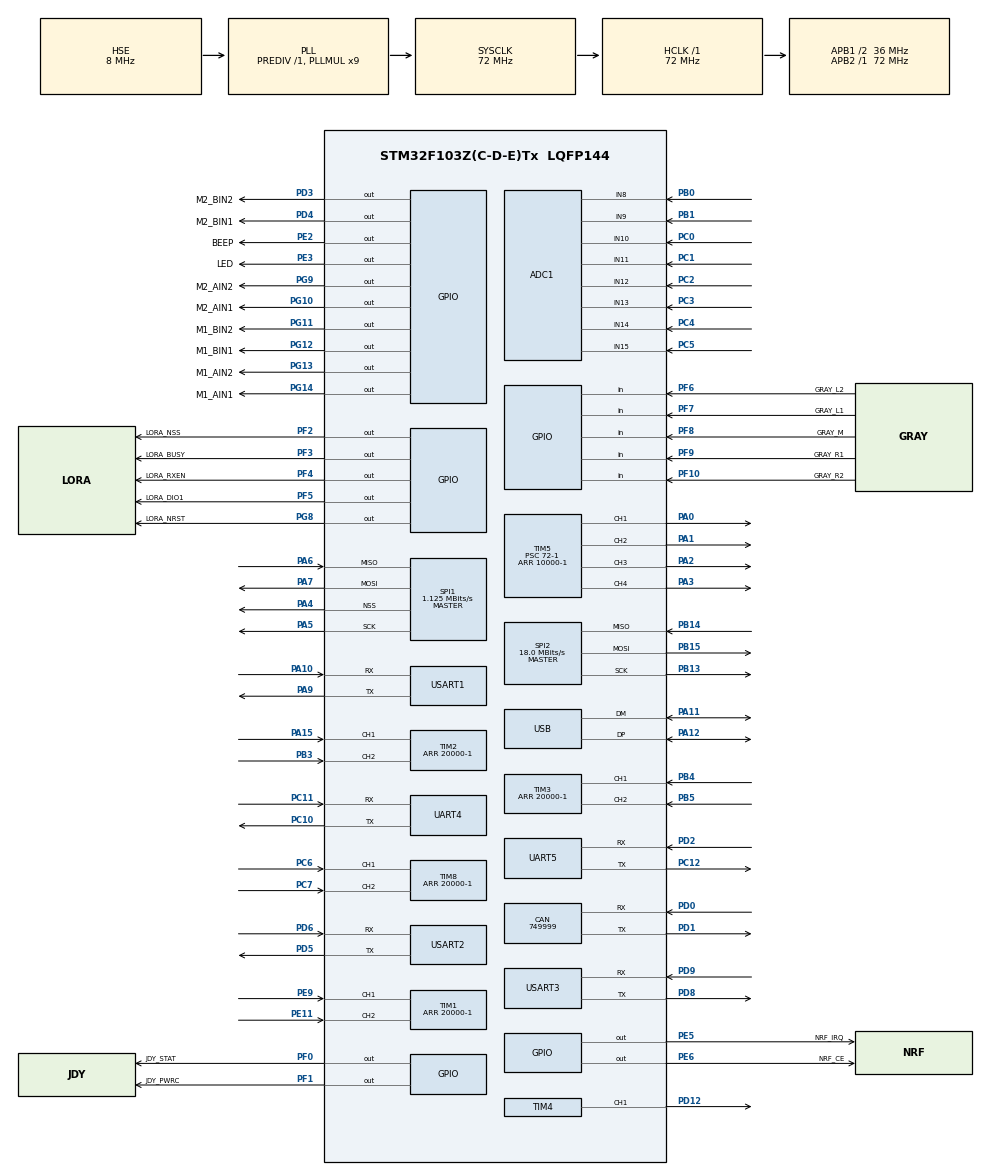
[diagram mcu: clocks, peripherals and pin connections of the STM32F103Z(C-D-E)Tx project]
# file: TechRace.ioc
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ADC1.Channel-1\#ChannelRegularConversion=ADC_CHANNEL_8
ADC1.Channel-2\#ChannelRegularConversion=ADC_CHANNEL_9
ADC1.Channel-4\#ChannelRegularConversion=ADC_CHANNEL_10
ADC1.Channel-5\#ChannelRegularConversion=ADC_CHANNEL_11
ADC1.Channel-6\#ChannelRegularConversion=ADC_CHANNEL_12
ADC1.Channel-7\#ChannelRegularConversion=ADC_CHANNEL_13
ADC1.Channel-8\#ChannelRegularConversion=ADC_CHANNEL_14
ADC1.Channel-9\#ChannelRegularConversion=ADC_CHANNEL_15
ADC1.ContinuousConvMode=ENABLE
ADC1.DataAlign=ADC_DATAALIGN_RIGHT
ADC1.NbrOfConversion=8
ADC1.NbrOfConversionFlag=1
ADC1.Rank-1\#ChannelRegularConversion=1
ADC1.Rank-2\#ChannelRegularConversion=2
ADC1.Rank-4\#ChannelRegularConversion=3
ADC1.Rank-5\#ChannelRegularConversion=4
ADC1.Rank-6\#ChannelRegularConversion=5
ADC1.Rank-7\#ChannelRegularConversion=6
ADC1.Rank-8\#ChannelRegularConversion=7
ADC1.Rank-9\#ChannelRegularConversion=8
ADC1.SamplingTime-1\#ChannelRegularConversion=ADC_SAMPLETIME_55CYCLES_5
ADC1.SamplingTime-2\#ChannelRegularConversion=ADC_SAMPLETIME_55CYCLES_5
ADC1.SamplingTime-4\#ChannelRegularConversion=ADC_SAMPLETIME_55CYCLES_5
ADC1.SamplingTime-5\#ChannelRegularConversion=ADC_SAMPLETIME_55CYCLES_5
ADC1.SamplingTime-6\#ChannelRegularConversion=ADC_SAMPLETIME_55CYCLES_5
ADC1.SamplingTime-7\#ChannelRegularConversion=ADC_SAMPLETIME_55CYCLES_5
ADC1.SamplingTime-8\#ChannelRegularConversion=ADC_SAMPLETIME_55CYCLES_5
ADC1.SamplingTime-9\#ChannelRegularConversion=ADC_SAMPLETIME_55CYCLES_5
ADC1.master=1
CAN.CalculateBaudRate=749999
CAN.CalculateTimeBit=1333
CAN.CalculateTimeQuantum=444.44444444444446
Dma.ADC1.0.Direction=DMA_PERIPH_TO_MEMORY
Dma.ADC1.0.Instance=DMA1_Channel1
Dma.ADC1.0.MemDataAlignment=DMA_MDATAALIGN_HALFWORD
Dma.ADC1.0.MemInc=DMA_MINC_ENABLE
Dma.ADC1.0.Mode=DMA_CIRCULAR
Dma.ADC1.0.PeriphDataAlignment=DMA_PDATAALIGN_HALFWORD
Dma.ADC1.0.PeriphInc=DMA_PINC_DISABLE
Dma.ADC1.0.Priority=DMA_PRIORITY_LOW
Dma.Request0=ADC1
Mcu.Family=STM32F1
Mcu.Name=STM32F103Z(C-D-E)Tx
Mcu.Package=LQFP144
NVIC.ADC1_2_IRQn=true\:2\:0\:true\:false\:true\:true\:true\:true
NVIC.DMA1_Channel1_IRQn=true\:0\:0\:false\:false\:true\:false\:true\:true
NVIC.PriorityGroup=NVIC_PRIORITYGROUP_4
NVIC.TIM6_IRQn=true\:0\:0\:false\:false\:true\:true\:true\:true
OSC_IN.Mode=HSE-External-Oscillator
OSC_IN.Signal=RCC_OSC_IN
OSC_OUT.Mode=HSE-External-Oscillator
OSC_OUT.Signal=RCC_OSC_OUT
PA0-WKUP.Signal=S_TIM5_CH1
PA1.Signal=S_TIM5_CH2
PA10.Mode=Asynchronous
PA10.Signal=USART1_RX
PA11.Mode=Device
PA11.Signal=USB_DM
PA12.Mode=Device
PA12.Signal=USB_DP
PA13.Mode=Serial_Wire
PA13.Signal=SYS_JTMS-SWDIO
PA14.Mode=Serial_Wire
PA14.Signal=SYS_JTCK-SWCLK
PA15.Signal=S_TIM2_CH1_ETR
PA2.Signal=S_TIM5_CH3
PA3.Signal=S_TIM5_CH4
PA4.Mode=NSS_Signal_Hard_Output
PA4.Signal=SPI1_NSS
PA5.Mode=Full_Duplex_Master
PA5.Signal=SPI1_SCK
PA6.Mode=Full_Duplex_Master
PA6.Signal=SPI1_MISO
PA7.Mode=Full_Duplex_Master
PA7.Signal=SPI1_MOSI
PA9.Mode=Asynchronous
PA9.Signal=USART1_TX
PB0.Signal=ADCx_IN8
PB1.Signal=ADCx_IN9
PB13.Mode=Full_Duplex_Master
PB13.Signal=SPI2_SCK
PB14.Mode=Full_Duplex_Master
PB14.Signal=SPI2_MISO
PB15.Mode=Full_Duplex_Master
PB15.Signal=SPI2_MOSI
PB3.Signal=S_TIM2_CH2
PB4.Signal=S_TIM3_CH1
PB5.Signal=S_TIM3_CH2
PC0.Signal=ADCx_IN10
PC1.Signal=ADCx_IN11
PC10.Mode=Asynchronous
PC10.Signal=UART4_TX
PC11.Mode=Asynchronous
PC11.Signal=UART4_RX
PC12.Mode=Asynchronous
PC12.Signal=UART5_TX
PC2.Signal=ADCx_IN12
PC3.Signal=ADCx_IN13
PC4.Signal=ADCx_IN14
PC5.Signal=ADCx_IN15
PC6.Signal=S_TIM8_CH1
PC7.Signal=S_TIM8_CH2
PD0.Mode=CAN_Activate
PD0.Signal=CAN_RX
PD1.Mode=CAN_Activate
PD1.Signal=CAN_TX
PD12.Signal=S_TIM4_CH1
PD2.Mode=Asynchronous
PD2.Signal=UART5_RX
PD3.GPIO_Label=M2_BIN2
PD3.Signal=GPIO_Output
PD4.GPIO_Label=M2_BIN1
PD4.Signal=GPIO_Output
PD5.Mode=Asynchronous
PD5.Signal=USART2_TX
PD6.Mode=Asynchronous
PD6.Signal=USART2_RX
PD8.Mode=Asynchronous
PD8.Signal=USART3_TX
PD9.Mode=Asynchronous
PD9.Signal=USART3_RX
PE11.Signal=S_TIM1_CH2
PE2.GPIO_Label=BEEP
PE2.GPIO_ModeDefaultOutputPP=GPIO_MODE_OUTPUT_PP
PE2.GPIO_PuPd=GPIO_PULLDOWN
PE2.GPIO_Speed=GPIO_SPEED_FREQ_HIGH
PE2.Signal=GPIO_Output
PE3.GPIO_Label=LED
PE3.GPIO_PuPd=GPIO_NOPULL
PE3.GPIO_Speed=GPIO_SPEED_FREQ_HIGH
PE3.PinState=GPIO_PIN_SET
PE3.Signal=GPIO_Output
PE5.GPIO_Label=NRF_IRQ
PE5.Signal=GPIO_Output
PE6.GPIO_Label=NRF_CE
PE6.Signal=GPIO_Output
PE9.Signal=S_TIM1_CH1
PF0.GPIO_Label=JDY_STAT
PF0.Signal=GPIO_Output
PF1.GPIO_Label=JDY_PWRC
PF1.Signal=GPIO_Output
PF10.GPIO_Label=GRAY_R2
PF10.Signal=GPIO_Input
PF2.GPIO_Label=LORA_NSS
PF2.Signal=GPIO_Output
PF3.GPIO_Label=LORA_BUSY
PF3.Signal=GPIO_Output
PF4.GPIO_Label=LORA_RXEN
PF4.Signal=GPIO_Output
PF5.GPIO_Label=LORA_DIO1
PF5.Signal=GPIO_Output
PF6.GPIO_Label=GRAY_L2
PF6.Signal=GPIO_Input
PF7.GPIO_Label=GRAY_L1
PF7.Signal=GPIO_Input
PF8.GPIO_Label=GRAY_M
PF8.Signal=GPIO_Input
PF9.GPIO_Label=GRAY_R1
PF9.Signal=GPIO_Input
PG10.GPIO_Label=M2_AIN1
PG10.Signal=GPIO_Output
PG11.GPIO_Label=M1_BIN2
PG11.Signal=GPIO_Output
PG12.GPIO_Label=M1_BIN1
PG12.Signal=GPIO_Output
PG13.GPIO_Label=M1_AIN2
PG13.Signal=GPIO_Output
PG14.GPIO_Label=M1_AIN1
PG14.Signal=GPIO_Output
PG8.GPIO_Label=LORA_NRST
PG8.Signal=GPIO_Output
PG9.GPIO_Label=M2_AIN2
PG9.Signal=GPIO_Output
ProjectManager.HeapSize=0x200
ProjectManager.StackSize=0x400
ProjectManager.TargetToolchain=MDK-ARM V5.32
RCC.ADCPresc=RCC_ADCPCLK2_DIV6
RCC.AHBFreq_Value=72000000
RCC.APB1CLKDivider=RCC_HCLK_DIV2
RCC.APB1Freq_Value=36000000
RCC.APB1TimFreq_Value=72000000
RCC.APB2Freq_Value=72000000
RCC.APB2TimFreq_Value=72000000
RCC.HCLKFreq_Value=72000000
RCC.PLLMUL=RCC_PLL_MUL9
RCC.PLLSourceVirtual=RCC_PLLSOURCE_HSE
RCC.SYSCLKFreq_VALUE=72000000
RCC.SYSCLKSource=RCC_SYSCLKSOURCE_PLLCLK
RCC.USBFreq_Value=48000000
RCC.USBPrescaler=RCC_USBCLKSOURCE_PLL_DIV1_5
SH.ADCx_IN10.0=ADC1_IN10,IN10
SH.ADCx_IN11.0=ADC1_IN11,IN11
SH.ADCx_IN12.0=ADC1_IN12,IN12
SH.ADCx_IN13.0=ADC1_IN13,IN13
SH.ADCx_IN14.0=ADC1_IN14,IN14
SH.ADCx_IN15.0=ADC1_IN15,IN15
SH.ADCx_IN8.0=ADC1_IN8,IN8
SH.ADCx_IN9.0=ADC1_IN9,IN9
SH.S_TIM1_CH1.0=TIM1_CH1,Encoder_Interface
SH.S_TIM1_CH2.0=TIM1_CH2,Encoder_Interface
SH.S_TIM2_CH1_ETR.0=TIM2_CH1,Encoder_Interface
SH.S_TIM2_CH2.0=TIM2_CH2,Encoder_Interface
SH.S_TIM3_CH1.0=TIM3_CH1,Encoder_Interface
SH.S_TIM3_CH2.0=TIM3_CH2,Encoder_Interface
SH.S_TIM4_CH1.0=TIM4_CH1,PWM Generation1 CH1
SH.S_TIM5_CH1.0=TIM5_CH1,PWM Generation1 CH1
SH.S_TIM5_CH2.0=TIM5_CH2,PWM Generation2 CH2
SH.S_TIM5_CH3.0=TIM5_CH3,PWM Generation3 CH3
SH.S_TIM5_CH4.0=TIM5_CH4,PWM Generation4 CH4
SH.S_TIM8_CH1.0=TIM8_CH1,Encoder_Interface
SH.S_TIM8_CH2.0=TIM8_CH2,Encoder_Interface
SPI1.BaudRatePrescaler=SPI_BAUDRATEPRESCALER_64
SPI1.CalculateBaudRate=1.125 MBits/s
SPI1.Direction=SPI_DIRECTION_2LINES
SPI1.Mode=SPI_MODE_MASTER
SPI1.VirtualNSS=VM_NSSHARD
SPI1.VirtualType=VM_MASTER
SPI2.BaudRatePrescaler=SPI_BAUDRATEPRESCALER_2
SPI2.CalculateBaudRate=18.0 MBits/s
SPI2.Direction=SPI_DIRECTION_2LINES
SPI2.Mode=SPI_MODE_MASTER
SPI2.VirtualType=VM_MASTER
TIM1.EncoderMode=TIM_ENCODERMODE_TI12
TIM1.Period=20000-1
TIM2.EncoderMode=TIM_ENCODERMODE_TI12
TIM2.Period=20000-1
TIM3.EncoderMode=TIM_ENCODERMODE_TI12
TIM3.Period=20000-1
TIM4.Channel-PWM\ Generation1\ CH1=TIM_CHANNEL_1
TIM5.Channel-PWM\ Generation1\ CH1=TIM_CHANNEL_1
TIM5.Channel-PWM\ Generation2\ CH2=TIM_CHANNEL_2
TIM5.Channel-PWM\ Generation3\ CH3=TIM_CHANNEL_3
TIM5.Channel-PWM\ Generation4\ CH4=TIM_CHANNEL_4
TIM5.Period=10000-1
TIM5.Prescaler=72-1
TIM6.Period=10000-1
TIM6.Prescaler=72-1
TIM8.EncoderMode=TIM_ENCODERMODE_TI12
TIM8.Period=20000-1
UART4.VirtualMode=Asynchronous
UART5.VirtualMode=Asynchronous
USART1.VirtualMode=VM_ASYNC
USART2.VirtualMode=VM_ASYNC
USART3.VirtualMode=VM_ASYNC
VP_TIM6_VS_ClockSourceINT.Mode=Enable_Timer
board=custom

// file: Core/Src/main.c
/* USER CODE BEGIN Header */
/**
 ******************************************************************************
 * @file           : main.c
 * @brief          : Main program body
 ******************************************************************************
 * @attention
 *
 * Copyright (c) 2023 STMicroelectronics.
 * All rights reserved.
 *
 * This software is licensed under terms that can be found in the LICENSE file
 * in the root directory of this software component.
 * If no LICENSE file comes with this software, it is provided AS-IS.
 *
 ******************************************************************************
 */
/* USER CODE END Header */
#include "main.h"
#include "adc.h"
#include "can.h"
#include "dma.h"
#include "spi.h"
#include "tim.h"
#include "usart.h"
#include "usb.h"
#include "gpio.h"

void SystemClock_Config(void);

int main(void)
{

  /* MCU Configuration--------------------------------------------------------*/

  /* Reset of all peripherals, Initializes the Flash interface and the Systick. */
  HAL_Init();

  /* Configure the system clock */
  SystemClock_Config();

  /* Initialize all configured peripherals */
  MX_GPIO_Init();
  MX_DMA_Init();
  MX_TIM1_Init();
  MX_TIM2_Init();
  MX_TIM3_Init();
  MX_TIM5_Init();
  MX_TIM6_Init();
  MX_TIM8_Init();
  MX_CAN_Init();
  MX_SPI1_Init();
  MX_SPI2_Init();
  MX_UART4_Init();
  MX_UART5_Init();
  MX_USART1_UART_Init();
  MX_USART2_UART_Init();
  MX_USART3_UART_Init();
  MX_USB_PCD_Init();
  MX_TIM4_Init();
  MX_ADC1_Init();
  /* USER CODE BEGIN 2 */
  I2C_Init();
  OLED_Init();
	MPU6050_Init();
//  OLED_Show_Num(100,3 ,MPU6050_Init(),16);
  OLED_Show_Num(100,5,run_self_test(),16);
  Motor_Init();
  MY_ADC_Init();

  /* USER CODE END 2 */

  /* Infinite loop */
  while (1)
  {

  }
}

void SystemClock_Config(void)
{
  RCC_OscInitTypeDef RCC_OscInitStruct = {0};
  RCC_ClkInitTypeDef RCC_ClkInitStruct = {0};
  RCC_PeriphCLKInitTypeDef PeriphClkInit = {0};

  /** Initializes the RCC Oscillators according to the specified parameters
  * in the RCC_OscInitTypeDef structure.
  */
  RCC_OscInitStruct.OscillatorType = RCC_OSCILLATORTYPE_HSE;
  RCC_OscInitStruct.HSEState = RCC_HSE_ON;
  RCC_OscInitStruct.HSEPredivValue = RCC_HSE_PREDIV_DIV1;
  RCC_OscInitStruct.HSIState = RCC_HSI_ON;
  RCC_OscInitStruct.PLL.PLLState = RCC_PLL_ON;
  RCC_OscInitStruct.PLL.PLLSource = RCC_PLLSOURCE_HSE;
  RCC_OscInitStruct.PLL.PLLMUL = RCC_PLL_MUL9;
  if (HAL_RCC_OscConfig(&RCC_OscInitStruct) != HAL_OK)
  {
    Error_Handler();
  }

  /** Initializes the CPU, AHB and APB buses clocks
  */
  RCC_ClkInitStruct.ClockType = RCC_CLOCKTYPE_HCLK|RCC_CLOCKTYPE_SYSCLK
                              |RCC_CLOCKTYPE_PCLK1|RCC_CLOCKTYPE_PCLK2;
  RCC_ClkInitStruct.SYSCLKSource = RCC_SYSCLKSOURCE_PLLCLK;
  RCC_ClkInitStruct.AHBCLKDivider = RCC_SYSCLK_DIV1;
  RCC_ClkInitStruct.APB1CLKDivider = RCC_HCLK_DIV2;
  RCC_ClkInitStruct.APB2CLKDivider = RCC_HCLK_DIV1;

  if (HAL_RCC_ClockConfig(&RCC_ClkInitStruct, FLASH_LATENCY_2) != HAL_OK)
  {
    Error_Handler();
  }
  PeriphClkInit.PeriphClockSelection = RCC_PERIPHCLK_ADC|RCC_PERIPHCLK_USB;
  PeriphClkInit.AdcClockSelection = RCC_ADCPCLK2_DIV6;
  PeriphClkInit.UsbClockSelection = RCC_USBCLKSOURCE_PLL_DIV1_5;
  if (HAL_RCCEx_PeriphCLKConfig(&PeriphClkInit) != HAL_OK)
  {
    Error_Handler();
  }
}

void Error_Handler(void)
{
  __disable_irq();
  while (1)
  {
  }
}
